# slabware register map
Registers are 32-bit, read-only, reset 0x0 unless marked. A register's access mark holds for its fields unless they carry their own. Offsets are from the block's base; [hi:lo] are bit positions; {n}, {i} and the like mark numbered series.

## HdmiRX — HDMI Receiver
Base 0x10000C00
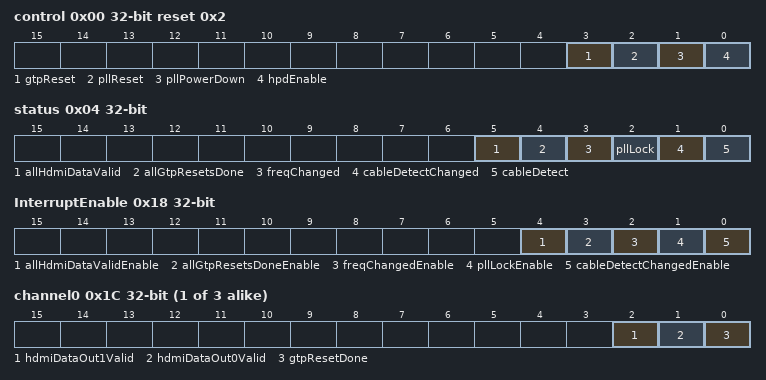
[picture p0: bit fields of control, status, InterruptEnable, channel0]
0x00 control rw reset 0x2
  [3] gtpReset read-modifies — GTP transceiver reset
  [2] pllReset read-modifies
  [1] pllPowerDown read-modifies
  [0] hpdEnable read-modifies — Hot plug detect enable
0x04 status access per field
  [5] allHdmiDataValid ro read-modifies — All channel data is valid
  [4] allGtpResetsDone ro read-modifies — All channel GTP resets done
  [3] freqChanged rw write-1-clears read-modifies — Clock detector frequency changed
  [2] pllLock ro read-modifies — PLL is locked
  [1] cableDetectChanged rw write-1-clears read-modifies — Cable detect status changed
  [0] cableDetect ro read-modifies
0x08 clkDetDivisor — Clock detector divisor
  [8:0] value read-modifies — Divisor value
0x0C clkDetSampleRate — Clock detector sample rate
  [9:0] value read-modifies — Sample rate in Hz
0x10 clkDetCount — Clock detector frequency count
  [10:0] value read-modifies — Frequency counter value
0x14 clkDetTolerance rw reset 0x1 — Clock detector tolerance
  [4:0] value read-modifies — Tolerance for frequency change detection
0x18 InterruptEnable rw — Interrupt enables
  [4] allHdmiDataValidEnable read-modifies — Enable all channel data is valid interrupt
  [3] allGtpResetsDoneEnable read-modifies — Enable all channel GTP resets done interrupt
  [2] freqChangedEnable read-modifies — Enable frequency change interrupt
  [1] pllLockEnable read-modifies — Enable PLL lock interrupt
  [0] cableDetectChangedEnable read-modifies — Enable cable detect changed interrupt
{0x1C+4i} channel{i} (i=0..2) — Channel {i} status
  [2] hdmiDataOut1Valid read-modifies — HDMI data out 1 is valid
  [1] hdmiDataOut0Valid read-modifies — HDMI data out 0 is valid
  [0] gtpResetDone read-modifies — GTP transceiver reset is done

## LcdDim — LCD dim control
Base 0x10001000
0x00 Control rw — PWM control
  [0] enable read-modifies — PWM output enable
0x04 Period rw reset 0xFF — PWM period
  [7:0] value read-modifies — PWM period value
0x08 Duty rw reset 0x7F — PWM duty
  [7:0] value read-modifies — PWM duty value

## GridCtrl — SlabGrid control
Base 0x10001400
0x00 Control rw — SlabGrid control
  [0] enable read-modifies — SlabGrid enable
0x04 ScanRate — Grid key scan rate
  [4:0] rate read-modifies — Key scan rate (25 Hz)
{0x8+4i} Col{i}KeyState (i=0..17) — Column {i} key state
  [7:0] state read-modifies — Colum {i} key state (row 0 is bit 0)

## UsbCtrl — USB device controller
Base 0x10010000
0xFF00 Frame — USB frame id
  [10:0] usbFrameId read-modifies — Current USB frame ID
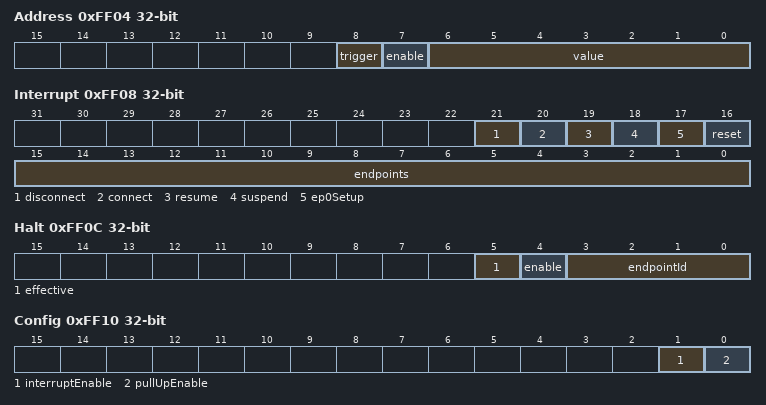
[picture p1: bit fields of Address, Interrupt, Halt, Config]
0xFF04 Address rw — USB address
  [8] trigger read-modifies — Set the enable (see above) on the next EP0 IN token completion Cleared by the hardware after any EP0 completion
  [7] enable read-modifies — Enable the USB address filtering if set
  [6:0] value read-modifies — The device will only listen at tokens with the specified address. This field is automatically cleared on usb reset events
0xFF08 Interrupt rw — Interrupt status
  [21] disconnect write-1-clears read-modifies — Raised when a USB disconnect occurs (no bus power)
  [20] connect write-1-clears read-modifies — Raised when a USB connect occurs (bus power)
  [19] resume write-1-clears read-modifies — Raised when a USB resume occurs
  [18] suspend write-1-clears read-modifies — Raised when a USB suspend occurs
  [17] ep0Setup write-1-clears read-modifies — Raised when endpoint 0 receives a setup transaction
  [16] reset write-1-clears read-modifies — Raised when a USB reset occurs
  [15:0] endpoints write-1-clears read-modifies — Raised when an endpoint generates an interrupt
0xFF0C Halt access per field — Halt endpoint
  [5] effective ro read-modifies — After setting the enable, wait for this bit to be set by the hardware to ensure atomicity
  [4] enable rw read-modifies — Halt is active when set, endpoint is unhalted when cleared.
  [3:0] endpointId rw read-modifies — The endpoint you want to put in sleep
0xFF10 Config rw — Configuration
  [1] interruptEnable read-modifies — Enable interrupts
  [0] pullUpEnable read-modifies — Enable USB device pullup on dp pin
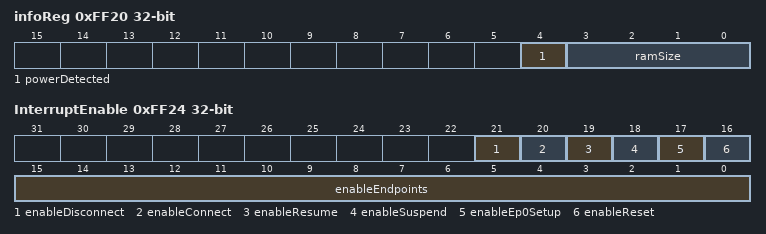
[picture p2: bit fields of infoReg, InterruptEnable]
0xFF20 infoReg — Info
  [4] powerDetected read-modifies — USB bus power detected
  [3:0] ramSize read-modifies — Internal ram address width (bits)
0xFF24 InterruptEnable rw
  [21] enableDisconnect read-modifies — Enable USB disconnect interrupt
  [20] enableConnect read-modifies — Enable USB connect interrupt
  [19] enableResume read-modifies — Enable USB resume interrupt
  [18] enableSuspend read-modifies — Enable USB suspend interrupt
  [17] enableEp0Setup read-modifies — Enable endpoint 0 setup interrupt
  [16] enableReset read-modifies — Enable USB reset interrupt
  [15:0] enableEndpoints read-modifies — Enable endpoint interrupt
